VERSION ""

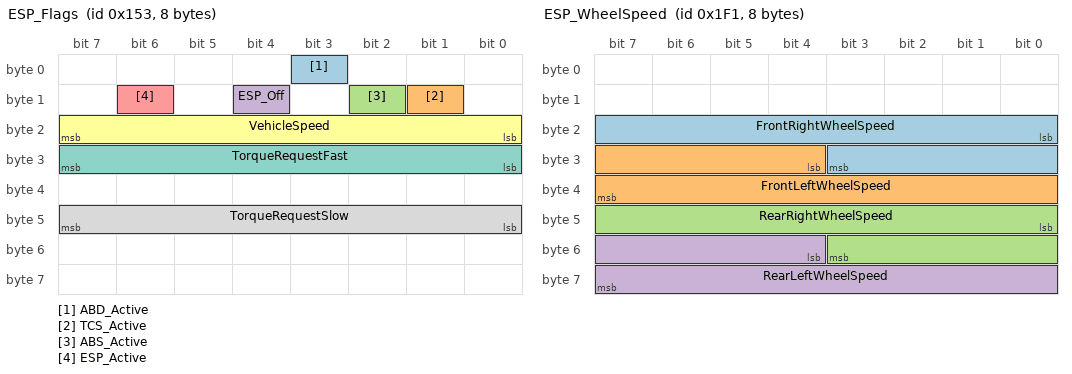
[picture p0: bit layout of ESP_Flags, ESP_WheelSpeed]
BO_ 339 ESP_Flags: 8 ESP
 SG_ ABD_Active : 3|1@1+ (1,0) [0|1] "yes/no"  AWD,ECU,TCU
 SG_ TCS_Active : 9|1@1+ (1,0) [0|1] "yes/no"  AWD,ECU,TCU
 SG_ ABS_Active : 10|1@1+ (1,0) [0|1] "yes/no"  AWD,ECU,TCU
 SG_ ESP_Off : 12|1@1+ (1,0) [0|1] "yes/no"  AWD,ECU,TCU
 SG_ ESP_Active : 14|1@1+ (1,0) [0|1] "yes/no"  AWD,ECU,TCU
 SG_ VehicleSpeed : 16|8@1+ (1,0) [0|254] "km/h"  AWD,ECU,TCU
 SG_ TorqueRequestFast : 24|8@1+ (0.390625,0) [0|99.609375] "%"  ECU,TCU
 SG_ TorqueRequestSlow : 40|8@1+ (0.390625,0) [0|99.609375] "%"  ECU,TCU

BO_ 497 ESP_WheelSpeed: 8 ESP
 SG_ FrontRightWheelSpeed : 16|12@1+ (0.125,0) [0|511.875] "km/h"  AWD
 SG_ FrontLeftWheelSpeed : 28|12@1+ (0.125,0) [0|511.875] "km/h"  AWD
 SG_ RearRightWheelSpeed : 40|12@1+ (0.125,0) [0|511.875] "km/h"  AWD
 SG_ RearLeftWheelSpeed : 52|12@1+ (0.125,0) [0|511.875] "km/h"  AWD

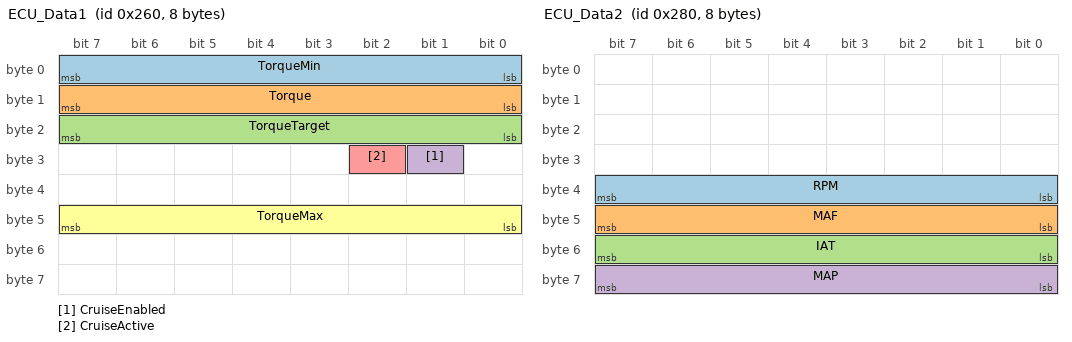
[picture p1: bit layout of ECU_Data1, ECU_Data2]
BO_ 608 ECU_Data1: 8 ECU
 SG_ TorqueMin : 0|8@1+ (0.390625,0) [0|99.609375] "%"  ESP,TCU
 SG_ Torque : 8|8@1+ (0.390625,0) [0|99.609375] "%"  ESP,TCU
 SG_ TorqueTarget : 16|8@1+ (0.390625,0) [0|99.609375] "%"  ESP,TCU
 SG_ CruiseEnabled : 25|1@1+ (1,0) [0|1] "yes/no"  TCU
 SG_ CruiseActive : 26|1@1+ (1,0) [0|1] "yes/no"  TCU
 SG_ TorqueMax : 40|8@1+ (0.390625,0) [0|99.609375] "%"  ESP,TCU

BO_ 640 ECU_Data2: 8 ECU
 SG_ RPM : 32|8@1+ (32,0) [0|8160] "rpm"  TCU
 SG_ MAF : 40|8@1+ (5.447,0) [0|1388.985] "mg/TDC"  TCU
 SG_ IAT : 48|8@1- (0.75,-48) [-48|143.25] "C"  TCU
 SG_ MAP : 56|8@1+ (0.47058,0) [0|119.9979] "KPa"  TCU

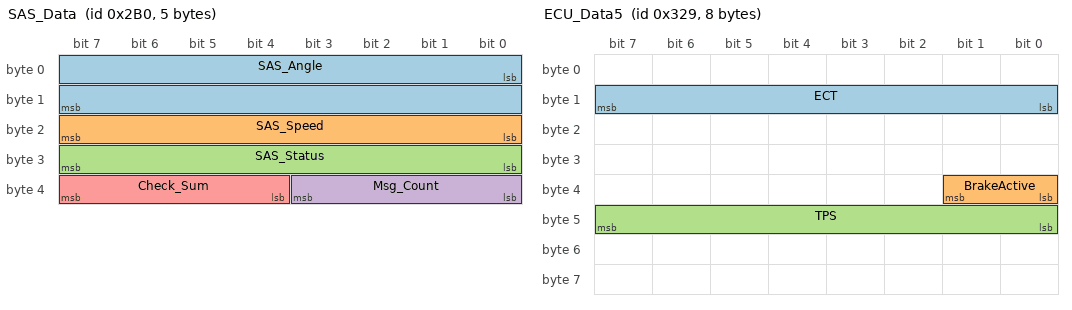
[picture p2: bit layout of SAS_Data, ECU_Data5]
BO_ 688 SAS_Data: 5 SAS
 SG_ SAS_Angle : 0|16@1- (0.1,0) [-3276.8|3276.7] "deg"  AWD,ECU,ESP,TCU
 SG_ SAS_Speed : 16|8@1+ (4,0) [0|1016] "deg/s"  ESP,TCU
 SG_ SAS_Status : 24|8@1+ (1,0) [0|255] ""  ESP,TCU
 SG_ Msg_Count : 32|4@1+ (1,0) [0|15] ""  ESP
 SG_ Check_Sum : 36|4@1+ (1,0) [0|15] ""  ECU,ESP

BO_ 809 ECU_Data5: 8 ECU
 SG_ ECT : 8|8@1- (0.75,-48) [-48|143.25] "C"  AWD,ABS,ESP,TCU
 SG_ BrakeActive : 32|2@1+ (1,0) [0|3] "yes/no"  AWD,ABS,ESP,TCU
 SG_ TPS : 40|8@1+ (0.47265625,-15) [-15|105.52734375] "%"  AWD,ABS,ESP,TCU

BO_ 1064 AWD_Data1: 8 AWD
 SG_ ClutchDuty : 16|8@1+ (1,0) [0|100] "%"  ABS,ESP
 SG_ ClutchLocked : 44|1@1+ (1,0) [0|1] "yes/no"  ABS,ESP

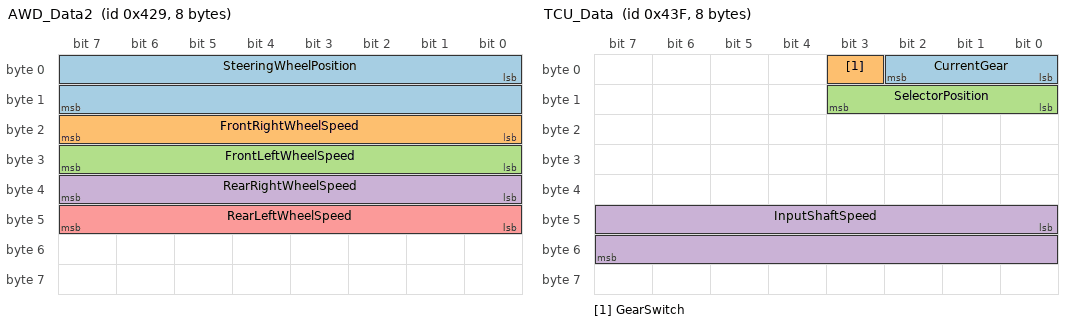
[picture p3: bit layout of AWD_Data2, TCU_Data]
BO_ 1065 AWD_Data2: 8 AWD
 SG_ SteeringWheelPosition : 0|16@1+ (1,-600) [-600|600] "deg"  ABS
 SG_ FrontRightWheelSpeed : 16|8@1+ (1,0) [0|254] "km/h"  ABS
 SG_ FrontLeftWheelSpeed : 24|8@1+ (1,0) [0|254] "km/h"  ABS
 SG_ RearRightWheelSpeed : 32|8@1+ (1,0) [0|254] "km/h"  ABS
 SG_ RearLeftWheelSpeed : 40|8@1+ (1,0) [0|254] "km/h"  ABS

BO_ 1087 TCU_Data: 8 TCU
 SG_ CurrentGear : 0|3@1+ (1,0) [0|7] ""  ECU
 SG_ GearSwitch : 3|1@1+ (1,0) [0|1] "yes/no"  ECU
 SG_ SelectorPosition : 8|4@1+ (1,0) [0|15] ""  ECU
 SG_ InputShaftSpeed : 40|16@1+ (0.25,0) [0|16383.5] "rpm"  ECU

BO_ 1349 ECU_Data6: 8 ECU
 SG_ BatteryVoltage : 24|8@1+ (0.1015625,0) [0|25.8984375] "V"  ABS,ESP

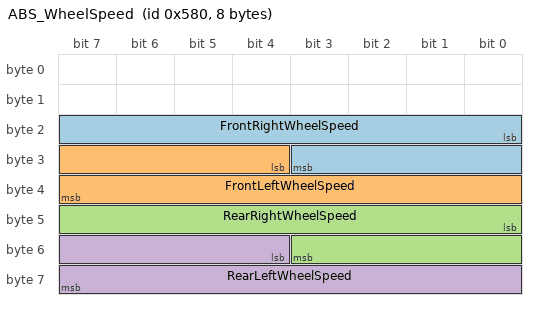
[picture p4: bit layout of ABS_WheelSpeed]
BO_ 1408 ABS_WheelSpeed: 8 ABS
 SG_ FrontRightWheelSpeed : 16|12@1+ (0.125,0) [0|511.875] "km/h"  AWD
 SG_ FrontLeftWheelSpeed : 28|12@1+ (0.125,0) [0|511.875] "km/h"  AWD
 SG_ RearRightWheelSpeed : 40|12@1+ (0.125,0) [0|511.875] "km/h"  AWD
 SG_ RearLeftWheelSpeed : 52|12@1+ (0.125,0) [0|511.875] "km/h"  AWD

BO_ 1695 ECU_Data7: 8 ECU
 SG_ ECU_Temperature : 8|8@1- (1,-28) [-28|227] "C"  TCU

BO_ 1984 SAS_Calibration: 2 ESP
 SG_ CCW : 0|4@1+ (1,0) [0|15] ""  SAS
 SG_ CID : 4|11@1+ (1,0) [0|2047] ""  SAS

BU_: XXX

CM_ SG_ 31 GEAR "13-P, 12-R, 11-N, 1-6-D";
VAL_ 513 STATE 5 "FAULT_TIMEOUT" 4 "FAULT_STARTUP" 3 "FAULT_SCE" 2 "FAULT_SEND" 1 "FAULT_BAD_CHECKSUM" 0 "NO_FAULT" ;

VAL_ 780 CRUISE_SPEED 255 "no_speed" 252 "stopped";
VAL_ 780 HUD_LEAD 3 "acc_off" 2 "solid_car" 1 "dashed_car" 0 "no_car";
VAL_ 884 DASHBOARD_ALERT 0 "none" 51 "acc_problem" 55 "cmbs_problem" 75 "key_not_detected" 79 "fasten_seatbelt" 111 "lkas_problem" 131 "brake_system_problem" 132 "brake_hold_problem" 139 "tbd" 161 "door_open";
VAL_ 891 WIPERS 4 "High" 2 "Low" 0 "Off";

VAL_ 506 FCW 3 "fcw" 2 "fcw" 1 "fcw" 0 "no_fcw";
VAL_ 506 CHIME 4 "double_chime" 3 "single_chime" 2 "continuous_chime" 1 "repeating_chime" 0 "no_chime";
VAL_ 506 AEB_STATUS 3 "aeb_prepare" 2 "aeb_ready" 1 "aeb_braking" 0 "no_aeb";
VAL_ 829 BEEP 3 "single_beep" 2 "triple_beep" 1 "repeated_beep" 0 "no_beep";

VAL_ 392 GEAR_SHIFTER 0 "S" 1 "P" 2 "R" 4 "N" 8 "D" ;
VAL_ 392 GEAR 26 "S" 4 "D" 3 "N" 2 "R" 1 "P" ;
VAL_ 399 STEER_STATUS 6 "tmp_fault" 5 "fault_1" 4 "no_torque_alert_2" 3 "low_speed_lockout" 2 "no_torque_alert_1" 0 "normal" ;
